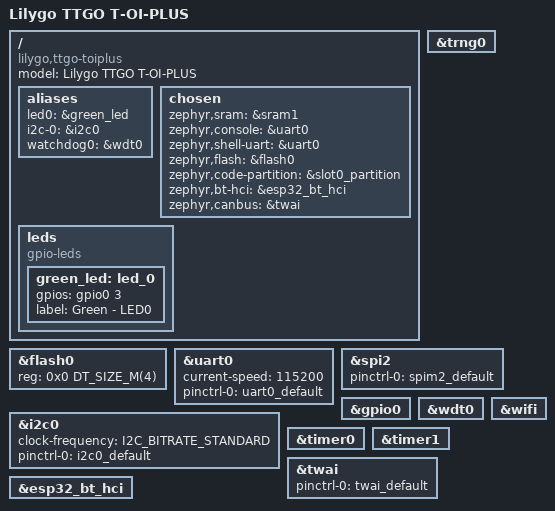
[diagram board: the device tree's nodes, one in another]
/*
 * Copyright 2025 aisuneko icecat <iceneko@protonmail.ch>
 *
 * SPDX-License-Identifier: Apache-2.0
 */

/dts-v1/;

#include <espressif/esp32c3/esp32c3_common.dtsi>
#include "ttgo_toiplus-pinctrl.dtsi"
#include <espressif/partitions_0x0_default.dtsi>

/ {
	model = "Lilygo TTGO T-OI-PLUS";
	compatible = "lilygo,ttgo-toiplus";

	aliases {
		led0 = &green_led;
		i2c-0 = &i2c0;
		watchdog0 = &wdt0;
	};

	chosen {
		zephyr,sram = &sram1;
		zephyr,console = &uart0;
		zephyr,shell-uart = &uart0;
		zephyr,flash = &flash0;
		zephyr,code-partition = &slot0_partition;
		zephyr,bt-hci = &esp32_bt_hci;
		zephyr,canbus = &twai;
	};

	leds {
		compatible = "gpio-leds";

		green_led: led_0 {
			gpios =  <&gpio0 3 GPIO_ACTIVE_HIGH>;
			label = "Green - LED0";
		};
	};
};

&flash0 {
	reg = <0x0 DT_SIZE_M(4)>;
};

&uart0 {
	status = "okay";
	current-speed = <115200>;
	pinctrl-0 = <&uart0_default>;
	pinctrl-names = "default";
};

&i2c0 {
	status = "okay";
	clock-frequency = <I2C_BITRATE_STANDARD>;
	pinctrl-0 = <&i2c0_default>;
	pinctrl-names = "default";
};

&trng0 {
	status = "okay";
};

&spi2 {
	#address-cells = <1>;
	#size-cells = <0>;
	status = "okay";
	pinctrl-0 = <&spim2_default>;
	pinctrl-names = "default";
};

&gpio0 {
	status = "okay";
};

&wdt0 {
	status = "okay";
};

&timer0 {
	status = "okay";
};

&timer1 {
	status = "okay";
};

&twai {
	status = "okay";
	pinctrl-0 = <&twai_default>;
	pinctrl-names = "default";
};

&wifi {
	status = "okay";
};

&esp32_bt_hci {
	status = "okay";
};
